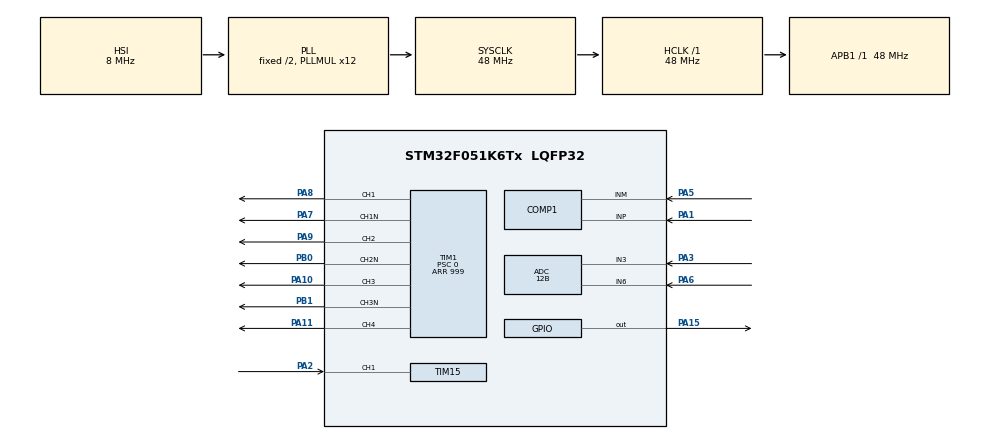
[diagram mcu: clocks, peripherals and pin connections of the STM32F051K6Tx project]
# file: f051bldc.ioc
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ADC.ClockPrescaler=ADC_CLOCK_ASYNC_DIV1
ADC.ContinuousConvMode=DISABLE
ADC.DMAContinuousRequests=ENABLE
ADC.DataAlign=ADC_DATAALIGN_RIGHT
ADC.DiscontinuousConvMode=ENABLE
ADC.EOCSelection=ADC_EOC_SEQ_CONV
ADC.EnableAnalogWatchDog=false
ADC.ExternalTrigConv=ADC_EXTERNALTRIGCONV_T1_CC4
ADC.ExternalTrigConvEdge=ADC_EXTERNALTRIGCONVEDGE_RISING
ADC.LowPowerAutoPowerOff=DISABLE
ADC.LowPowerAutoWait=DISABLE
ADC.Overrun=ADC_OVR_DATA_PRESERVED
ADC.Resolution=ADC_RESOLUTION_12B
ADC.SamplingTime=ADC_SAMPLETIME_239CYCLES_5
ADC.ScanConvMode=ADC_SCAN_DIRECTION_FORWARD
COMP1.Hysteresis=COMP_HYSTERESIS_LOW
COMP1.TriggerMode=COMP_TRIGGERMODE_IT_RISING_FALLING
Dma.ADC.1.Direction=DMA_PERIPH_TO_MEMORY
Dma.ADC.1.Instance=DMA1_Channel1
Dma.ADC.1.MemDataAlignment=DMA_MDATAALIGN_WORD
Dma.ADC.1.MemInc=DMA_MINC_ENABLE
Dma.ADC.1.Mode=DMA_CIRCULAR
Dma.ADC.1.PeriphDataAlignment=DMA_PDATAALIGN_WORD
Dma.ADC.1.PeriphInc=DMA_PINC_DISABLE
Dma.ADC.1.Priority=DMA_PRIORITY_LOW
Dma.Request0=TIM15_CH1/UP/TRIG/COM
Dma.Request1=ADC
Dma.TIM15_CH1/UP/TRIG/COM.0.Direction=DMA_PERIPH_TO_MEMORY
Dma.TIM15_CH1/UP/TRIG/COM.0.Instance=DMA1_Channel5
Dma.TIM15_CH1/UP/TRIG/COM.0.MemDataAlignment=DMA_MDATAALIGN_WORD
Dma.TIM15_CH1/UP/TRIG/COM.0.MemInc=DMA_MINC_ENABLE
Dma.TIM15_CH1/UP/TRIG/COM.0.Mode=DMA_NORMAL
Dma.TIM15_CH1/UP/TRIG/COM.0.PeriphDataAlignment=DMA_PDATAALIGN_HALFWORD
Dma.TIM15_CH1/UP/TRIG/COM.0.PeriphInc=DMA_PINC_DISABLE
Dma.TIM15_CH1/UP/TRIG/COM.0.Priority=DMA_PRIORITY_MEDIUM
IWDG.Prescaler=IWDG_PRESCALER_16
IWDG.Reload=4000
IWDG.Window=4095
Mcu.Family=STM32F0
Mcu.Name=STM32F051K6Tx
Mcu.Package=LQFP32
NVIC.ADC1_COMP_IRQn=true\:0\:0\:true\:false\:true\:false\:true
NVIC.DMA1_Channel1_IRQn=true\:2\:0\:true\:false\:true\:false\:true
NVIC.DMA1_Channel4_5_IRQn=true\:2\:0\:true\:false\:true\:false\:true
NVIC.TIM16_IRQn=true\:1\:0\:true\:false\:true\:true\:true
PA1.Mode=INP
PA1.Signal=COMP1_INP
PA10.Signal=S_TIM1_CH3
PA11.Signal=S_TIM1_CH4
PA13.Mode=Serial_Wire
PA13.Signal=SYS_SWDIO
PA14.Mode=Serial_Wire
PA14.Signal=SYS_SWCLK
PA15.Signal=GPIO_Output
PA2.Signal=S_TIM15_CH1
PA3.Mode=IN3
PA3.Signal=ADC_IN3
PA5.Mode=INM
PA5.Signal=COMP1_INM
PA6.Mode=IN6
PA6.Signal=ADC_IN6
PA7.Mode=PWM Generation1 CH1 CH1N
PA7.Signal=TIM1_CH1N
PA8.Signal=S_TIM1_CH1
PA9.Signal=S_TIM1_CH2
PB0.Mode=PWM Generation2 CH2 CH2N
PB0.Signal=TIM1_CH2N
PB1.Mode=PWM Generation3 CH3 CH3N
PB1.Signal=TIM1_CH3N
ProjectManager.HeapSize=0x200
ProjectManager.StackSize=0x400
ProjectManager.TargetToolchain=TrueSTUDIO
RCC.AHBFreq_Value=48000000
RCC.APB1Freq_Value=48000000
RCC.APB1TimFreq_Value=48000000
RCC.HCLKFreq_Value=48000000
RCC.PLLMUL=RCC_PLL_MUL12
RCC.SYSCLKFreq_VALUE=48000000
RCC.SYSCLKSource=RCC_SYSCLKSOURCE_PLLCLK
SH.S_TIM15_CH1.0=TIM15_CH1,Input_Capture1_from_TI1
SH.S_TIM15_CH1.1=TIM15_CH1,TriggerSource_TI1FP1
SH.S_TIM1_CH1.0=TIM1_CH1,PWM Generation1 CH1 CH1N
SH.S_TIM1_CH2.0=TIM1_CH2,PWM Generation2 CH2 CH2N
SH.S_TIM1_CH3.0=TIM1_CH3,PWM Generation3 CH3 CH3N
SH.S_TIM1_CH4.0=TIM1_CH4,PWM Generation4 CH4
TIM1.Channel-PWM\ Generation1\ CH1\ CH1N=TIM_CHANNEL_1
TIM1.Channel-PWM\ Generation2\ CH2\ CH2N=TIM_CHANNEL_2
TIM1.Channel-PWM\ Generation3\ CH3\ CH3N=TIM_CHANNEL_3
TIM1.Channel-PWM\ Generation4\ CH4=TIM_CHANNEL_4
TIM1.CounterMode=TIM_COUNTERMODE_CENTERALIGNED1
TIM1.DeadTime=60
TIM1.Period=999
TIM1.Prescaler=0
TIM1.TIM_MasterOutputTrigger=TIM_TRGO_RESET
TIM1.TIM_MasterSlaveMode=TIM_MASTERSLAVEMODE_DISABLE
TIM15.Channel-Input_Capture1_from_TI1=TIM_CHANNEL_1
TIM15.ICPolarity_CH1=TIM_INPUTCHANNELPOLARITY_BOTHEDGE
TIM15.Period=0xffff
TIM16.Period=9000
TIM2.Period=5000
TIM2.Prescaler=100
TIM3.Period=65535
TIM3.Prescaler=10
VP_ADC_TempSens_Input.Mode=IN-TempSens
VP_IWDG_VS_IWDG.Mode=IWDG_Activate
VP_TIM15_VS_ControllerModeReset.Mode=Reset Mode
VP_TIM16_VS_ClockSourceINT.Mode=Enable_Timer
VP_TIM1_VS_ClockSourceINT.Mode=Internal
VP_TIM2_VS_ClockSourceINT.Mode=Internal
VP_TIM3_VS_ClockSourceINT.Mode=Internal
board=f051bldc

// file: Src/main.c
/**
  ******************************************************************************
  * File Name          : main.c
  * Description        : Main program body
  ******************************************************************************
  ** This notice applies to any and all portions of this file
  * that are not between comment pairs USER CODE BEGIN and
  * USER CODE END. Other portions of this file, whether
  * inserted by the user or by software development tools
  * are owned by their respective copyright owners.
  *
  * COPYRIGHT(c) 2019 STMicroelectronics
  *
  * Redistribution and use in source and binary forms, with or without modification,
  * are permitted provided that the following conditions are met:
  *   1. Redistributions of source code must retain the above copyright notice,
  *      this list of conditions and the following disclaimer.
  *   2. Redistributions in binary form must reproduce the above copyright notice,
  *      this list of conditions and the following disclaimer in the documentation
  *      and/or other materials provided with the distribution.
  *   3. Neither the name of STMicroelectronics nor the names of its contributors
  *      may be used to endorse or promote products derived from this software
  *      without specific prior written permission.
  *
  * THIS SOFTWARE IS PROVIDED BY THE COPYRIGHT HOLDERS AND CONTRIBUTORS "AS IS"
  * AND ANY EXPRESS OR IMPLIED WARRANTIES, INCLUDING, BUT NOT LIMITED TO, THE
  * IMPLIED WARRANTIES OF MERCHANTABILITY AND FITNESS FOR A PARTICULAR PURPOSE ARE
  * DISCLAIMED. IN NO EVENT SHALL THE COPYRIGHT HOLDER OR CONTRIBUTORS BE LIABLE
  * FOR ANY DIRECT, INDIRECT, INCIDENTAL, SPECIAL, EXEMPLARY, OR CONSEQUENTIAL
  * DAMAGES (INCLUDING, BUT NOT LIMITED TO, PROCUREMENT OF SUBSTITUTE GOODS OR
  * SERVICES; LOSS OF USE, DATA, OR PROFITS; OR BUSINESS INTERRUPTION) HOWEVER
  * CAUSED AND ON ANY THEORY OF LIABILITY, WHETHER IN CONTRACT, STRICT LIABILITY,
  * OR TORT (INCLUDING NEGLIGENCE OR OTHERWISE) ARISING IN ANY WAY OUT OF THE USE
  * OF THIS SOFTWARE, EVEN IF ADVISED OF THE POSSIBILITY OF SUCH DAMAGE.
  *
  ******************************************************************************
  */

#include "main.h"
#include "stm32f0xx_hal.h"

/* USER CODE BEGIN Includes */
#include "eeprom.h"
/* USER CODE END Includes */

ADC_HandleTypeDef hadc;
DMA_HandleTypeDef hdma_adc;

COMP_HandleTypeDef hcomp1;

IWDG_HandleTypeDef hiwdg;

TIM_HandleTypeDef htim1;
TIM_HandleTypeDef htim2;
TIM_HandleTypeDef htim3;
TIM_HandleTypeDef htim15;
TIM_HandleTypeDef htim16;
DMA_HandleTypeDef hdma_tim15_ch1_up_trig_com;

/* USER CODE BEGIN PV */
/* Private variables ---------------------------------------------------------*/

#define MP6531
//#define FD6288

uint16_t VirtAddVarTab[NB_OF_VAR] = {0x5555, 0x6666, 0x7777};
uint16_t VarDataTab[NB_OF_VAR] = {0, 0, 0};
uint16_t VarValue,VarDataTmp;

uint32_t ee_status;

// variables to use for eeprom function,  ie: EE_WriteVariable(VirtAddVarTab[EEvehiclemode],  vehicle_mode ;

enum userVars{
	EEvehiclemode = 0,
	EEdirection = 1,
	EEbidirection = 2,
//	EEbrake_on_stop = 3
};
char brushed_mode = 0;
char vehicle_mode = 2;    // 1 = quad mode / eeprom load mode , 2 = crawler / thruster mode,  3 = rc car mode,  4 = like car mode but with auto reverse after stop  5 = no eeprom !!!!

char bi_polar = 0;
char polling_mode = 0;  // for better low speed accuracy

int dead_time = 60;           // change to 60 for qfn

int dir_reversed = 0;   // global direction reversed set in eeprom
int step = 1;
int startcount = 0;
int deviation = 0;
uint32_t extiline;

int forcedcomcount = 0;
int commandcount = 0;
char bad_commutation = 0;

int bi_direction = 0;
char comp_pwm = 1;                      // for complementary pwm , 0 for diode freewheeling
int brake = 1;                          // apply full motor brake on stop
int start_power = 200;
char prop_brake = 0;
int prop_brake_strength = 300;
int IC_buffer_size = 64;

char prop_brake_active = 0;
int adjusted_input;

int dshotcommand = 0;
uint8_t calcCRC;
uint8_t checkCRC;
int error = 0;
int stop_time =0;

int quietmode = 0;
int count = 0;
int tempbrake = 0;

char advancedivisor = 12;                    // increase divisor to decrease advance,
char advancedivisorup = 3;
char advancedivisordown = 3;
int advance_multiplier = 10;

int dither_count;
int dither_amount = 10;

int thiszctime = 0;
int lastzctime = 0;
int sensorless = 0;
int commutation_interval = 0;
int advance = 0;                       // set proportianal to commutation time. with advance divisor
int blanktime;
int pwm_settle = 50;
int demagtime = 5;
int waitTime = 0;
char filter_level = 1;
char compit = 0;
int filter_delay = 2;

int total;

int max_servo_deviation = 90;

int filter_level_up = 8;
int filter_level_down = 8;
int forcedcount = 0;
int control_loop_count;
int zctimeout = 0;
int zc_timeout_threshold = 2400;   // depends on speed of main loop

int signaltimeout = 0;
int signal_timeout_threshold = 20000;

int temp_step;
int ROC = 1;
int tocheck = 0;

int tim2_start_arr = 9000;
int startupcountdown = 0;

int duty_cycle = 100;

int pwm = 1;
int floating = 2;
int lowside = 3;
int bemf_counts;
int k_erpm;

int degree_time;

int forward = 1;
int rising = 1;
int running = 0;
int started = 0;
char armed = 0;
int armedcount = 0;

int input_buffer_size = 64;
int smallestnumber = 20000;
uint32_t dma_buffer[64];
int propulse[4] = {0,0,0,0};
int dpulse[16] =  {0,0,0,0,0,0,0,0,0,0,0,0,0,0,0,0};

int input = 0;
int newinput =0;
int servorawinput = 0;

int voltageraw = 0;
int currentraw = 0;
int tempraw = 0;
uint32_t ADC1ConvertedValues[2] = {0,0};
int timestamp;

int compcount = 0;
int upcompcount = 0;
int falsecount = 0;
int falsethreshold = 2;
int zcfound = 1;
int threshold = 6;
int upthreshold = 6;
int forced_com_done = 0;

char dshot = 0;
char proshot = 0;
char multishot = 0;
char oneshot42 = 0;
char oneshot125 = 0;
char servoPwm = 0;

char brushed_direction_set = 0;

char inputSet = 0;

const int pwmSin[] = {128,130,132,134,136,139,141,143,
145,147,150,152,154,156,158,160,
163,165,167,169,171,173,175,177,
179,181,183,185,187,189,191,193,
195,197,199,201,202,204,206,208,
209,211,213,214,216,218,219,221,
222,224,225,227,228,229,231,232,
233,234,236,237,238,239,240,241,
242,243,244,245,246,247,247,248,
249,249,250,251,251,252,252,253,
253,253,254,254,254,255,255,255,
255,255,255,255,255,255,255,255,
254,254,254,253,253,253,252,252,
251,251,250,249,249,248,247,247,
246,245,244,243,242,241,240,239,
238,237,236,234,233,232,231,229,
228,227,225,224,222,221,219,218,
216,214,213,211,209,208,206,204,
202,201,199,197,195,193,191,189,
187,185,183,181,179,177,175,173,
171,169,167,165,163,160,158,156,
154,152,150,147,145,143,141,139,
136,134,132,130,128,125,123,121,
119,116,114,112,110,108,105,103,
101,99,97,95,92,90,88,86,
84,82,80,78,76,74,72,70,
68,66,64,62,60,58,56,54,
53,51,49,47,46,44,42,41,
39,37,36,34,33,31,30,28,
27,26,24,23,22,21,19,18,
17,16,15,14,13,12,11,10,
9,8,8,7,6,6,5,4,
4,3,3,2,2,2,1,1,
1,0,0,0,0,0,0,0,
0,0,0,0,1,1,1,2,
2,2,3,3,4,4,5,6,
6,7,8,8,9,10,11,12,
13,14,15,16,17,18,19,21,
22,23,24,26,27,28,30,31,
33,34,36,37,39,41,42,44,
46,47,49,51,53,54,56,58,
60,62,64,66,68,70,72,74,
76,78,80,82,84,86,88,90,
92,95,97,99,101,103,105,108,
110,112,114,116,119,121,123,125};

int phase_A_position;
int phase_B_position;
int phase_C_position;
int step_delay  = 100;
char stepper_sine = 0;

/* USER CODE END PV */

void SystemClock_Config(void);
static void MX_GPIO_Init(void);
static void MX_DMA_Init(void);
static void MX_ADC_Init(void);
static void MX_COMP1_Init(void);
static void MX_TIM1_Init(void);
static void MX_TIM2_Init(void);
static void MX_TIM3_Init(void);
static void MX_TIM15_Init(void);
static void MX_IWDG_Init(void);
static void MX_TIM16_Init(void);

void HAL_TIM_MspPostInit(TIM_HandleTypeDef *htim);

/* USER CODE BEGIN PFP */
/* Private function prototypes -----------------------------------------------*/
long map(long x, long in_min, long in_max, long out_min, long out_max)
{
	if (x < in_min){
		x = in_min;
	}
	if (x > in_max){
		x = in_max;
	}
	return (x - in_min) * (out_max - out_min) / (in_max - in_min) + out_min;

}

void storeEEpromConfig(){

	 EE_WriteVariable(VirtAddVarTab[EEvehiclemode], vehicle_mode);
	 EE_WriteVariable(VirtAddVarTab[EEdirection], dir_reversed);
	 EE_WriteVariable(VirtAddVarTab[EEbidirection], bi_direction);
	// EE_WriteVariable(VirtAddVarTab[EEbrake_on_stop], EEbrake_on_stop);

	// playEEpromSavedTune();
}

void loadEEpromConfig(){
	 EE_ReadVariable(VirtAddVarTab[EEvehiclemode], &VarDataTab[EEvehiclemode]);
	 EE_ReadVariable(VirtAddVarTab[EEdirection], &VarDataTab[EEdirection]);
	 EE_ReadVariable(VirtAddVarTab[EEbidirection], &VarDataTab[EEbidirection]);
//	 EE_ReadVariable(VirtAddVarTab[EEbrake_on_stop], &VarDataTab[EEbrake_on_stop]);

	 if (VarDataTab[EEvehiclemode] == 0){             // nothing in the eeprom
     storeEEpromConfig();            // store default values
	 }else{
	 vehicle_mode = VarDataTab[EEvehiclemode];
	 dir_reversed = VarDataTab[EEdirection];
	 bi_direction = VarDataTab[EEbidirection];
//	 brake = VarDataTab[EEbrake_on_stop];
	 }
}

int getAbsDif(int number1, int number2){
	int result = number1 - number2;
	if (result < 0) {
	    result = -result;
	}
	return result;
}

//////////////////////////////////PHASE 1//////////////////////
#ifdef MP6531
void phaseAPWM() {  // phaseB qfnf051 , phase A qfp32
#endif
#ifdef FD6288
void phaseBPWM() {
#endif

		if(!comp_pwm  || prop_brake_active){            // for future
		LL_GPIO_SetPinMode(GPIOB, GPIO_PIN_0, LL_GPIO_MODE_OUTPUT);
		GPIOB->BRR = GPIO_PIN_0;
		}else{
		LL_GPIO_SetPinMode(GPIOB, GPIO_PIN_0, LL_GPIO_MODE_ALTERNATE); // low
		}
		LL_GPIO_SetPinMode(GPIOA, GPIO_PIN_9, LL_GPIO_MODE_ALTERNATE);  // high

	}

#ifdef MP6531
void phaseAFLOAT() {  // phaseB qfnf051 , phase A qfp32
#endif
#ifdef FD6288
void phaseBFLOAT() {
#endif

		LL_GPIO_SetPinMode(GPIOB, GPIO_PIN_0, LL_GPIO_MODE_OUTPUT);
		GPIOB->BRR = GPIO_PIN_0;
		LL_GPIO_SetPinMode(GPIOA, GPIO_PIN_9, LL_GPIO_MODE_OUTPUT);
		GPIOA->BRR = GPIO_PIN_9;
	}

#ifdef MP6531
void phaseALOW() {  // phaseB qfnf051 , phase A qfp32
#endif
#ifdef FD6288
void phaseBLOW() {
#endif

	        // low mosfet on
		LL_GPIO_SetPinMode(GPIOB, GPIO_PIN_0, LL_GPIO_MODE_OUTPUT);
		GPIOB->BSRR = GPIO_PIN_0;
		LL_GPIO_SetPinMode(GPIOA, GPIO_PIN_9, LL_GPIO_MODE_OUTPUT);
		GPIOA->BRR = GPIO_PIN_9;
	}

//////////////////////////////PHASE 2//////////////////////////////////////////////////

#ifdef MP6531
void phaseBPWM() {                                // phase c qfn , phase b qfp
#endif
#ifdef FD6288
void phaseCPWM() {
#endif

		if (!comp_pwm || prop_brake_active){
			LL_GPIO_SetPinMode(GPIOA, GPIO_PIN_7, LL_GPIO_MODE_OUTPUT);
			GPIOA->BRR = GPIO_PIN_7;
		}else{
		LL_GPIO_SetPinMode(GPIOA, GPIO_PIN_7, LL_GPIO_MODE_ALTERNATE);
		}
		LL_GPIO_SetPinMode(GPIOA, GPIO_PIN_8, LL_GPIO_MODE_ALTERNATE);

	}

#ifdef MP6531
void phaseBFLOAT() {                                // phase c qfn , phase b qfp
#endif
#ifdef FD6288
void phaseCFLOAT() {
#endif

	         // floating
		LL_GPIO_SetPinMode(GPIOA, GPIO_PIN_7, LL_GPIO_MODE_OUTPUT);
		GPIOA->BRR = GPIO_PIN_7;
		LL_GPIO_SetPinMode(GPIOA, GPIO_PIN_8, LL_GPIO_MODE_OUTPUT);
		GPIOA->BRR = GPIO_PIN_8;
	}

#ifdef MP6531
void phaseBLOW() {                                // phase c qfn , phase b qfp
#endif
#ifdef FD6288
void phaseCLOW() {
#endif

	            // lowside
		LL_GPIO_SetPinMode(GPIOA, GPIO_PIN_7, LL_GPIO_MODE_OUTPUT);
		GPIOA->BSRR = GPIO_PIN_7;
		LL_GPIO_SetPinMode(GPIOA, GPIO_PIN_8, LL_GPIO_MODE_OUTPUT);
		GPIOA->BRR = GPIO_PIN_8;
	}

///////////////////////////////////////////////PHASE 3 /////////////////////////////////////////////////

#ifdef MP6531
void phaseCPWM() {                    // phaseA qfn , phase C qfp
#endif
#ifdef FD6288
void phaseAPWM() {
#endif

		if (!comp_pwm || prop_brake_active){
			LL_GPIO_SetPinMode(GPIOB, GPIO_PIN_1, LL_GPIO_MODE_OUTPUT);
			GPIOB->BRR = GPIO_PIN_1;
			}else{
		LL_GPIO_SetPinMode(GPIOB, GPIO_PIN_1, LL_GPIO_MODE_ALTERNATE);
			}
		LL_GPIO_SetPinMode(GPIOA, GPIO_PIN_10, LL_GPIO_MODE_ALTERNATE);

	}

#ifdef MP6531
void phaseCFLOAT() {                    // phaseA qfn , phase C qfp
#endif
#ifdef FD6288
void phaseAFLOAT() {
#endif

		LL_GPIO_SetPinMode(GPIOB, GPIO_PIN_1, LL_GPIO_MODE_OUTPUT);
		GPIOB->BRR = GPIO_PIN_1;
		LL_GPIO_SetPinMode(GPIOA, GPIO_PIN_10, LL_GPIO_MODE_OUTPUT);
		GPIOA->BRR = GPIO_PIN_10;
	}

#ifdef MP6531
void phaseCLOW() {                    // phaseA qfn , phase C qfp
#endif
#ifdef FD6288
void phaseALOW() {
#endif

		LL_GPIO_SetPinMode(GPIOB, GPIO_PIN_1, LL_GPIO_MODE_OUTPUT);
		GPIOB->BSRR = GPIO_PIN_1;
		LL_GPIO_SetPinMode(GPIOA, GPIO_PIN_10, LL_GPIO_MODE_OUTPUT);
		GPIOA->BRR = GPIO_PIN_10;
	}

void  comStep (int newStep){
//TIM14->CNT = 0;
switch(newStep)
{

        case 1:			//A-B
        	phaseAPWM();
        	phaseBLOW();
        	phaseCFLOAT();
        	break;

        case 2:		// C-B
        	phaseAFLOAT();
        	phaseBLOW();
        	phaseCPWM();
        	break;

        case 3:	// C-A
        	phaseALOW();
        	phaseBFLOAT();
        	phaseCPWM();
        	break;

        case 4:// B-A
        	phaseALOW();
        	phaseBPWM();
        	phaseCFLOAT();
        	break;

        case 5:    // B-C
        	phaseAFLOAT();
        	phaseBPWM();
        	phaseCLOW();
        	break;

        case 6:      // A-C
        	phaseAPWM();
        	phaseBFLOAT();
        	phaseCLOW();
        	break;
	}

//stop_time = TIM14->CNT;

}

void allOff() {                   // coast
	phaseAFLOAT();
	phaseBFLOAT();
	phaseCFLOAT();
}

void fullBrake(){                     // full braking shorting all low sides
	phaseALOW();
	phaseBLOW();
	phaseCLOW();
}

void proBrake(){                    // duty cycle controls braking strength
//	prop_brake_active = 1;       // will turn off lower fets so only high side is active
	phaseAPWM();
	phaseBPWM();
	phaseCPWM();
}

void changeCompInput() {
//	TIM2->CNT = 0;
//	HAL_COMP_Stop_IT(&hcomp1);            // done in comparator routine

	if (step == 1 || step == 4) {   // c floating
	//	hcomp1.Init.InvertingInput = COMP_INVERTINGINPUT_IO1;
		COMP->CSR = 0b1100001;
	}

	if (step == 2 || step == 5) {     // a floating
#ifdef MP6531
		//COMP->CSR = 0x40;
	//	hcomp1.Init.InvertingInput = COMP_INVERTINGINPUT_DAC1;
		COMP->CSR = 0b1000001;                        /// if f051k6  step 2 , 5 is dac 1 ( swap comp input)
#endif
#ifdef FD6288
	//hcomp1.Init.InvertingInput = COMP_INVERTINGINPUT_DAC2;
		COMP->CSR = 0b1010001;
#endif
	}

	if (step == 3 || step == 6) {      // b floating
#ifdef MP6531
		//COMP->CSR = 0x50
	//	hcomp1.Init.InvertingInput = COMP_INVERTINGINPUT_DAC2;
		COMP->CSR = 0b1010001;
#endif
#ifdef FD6288
	//	hcomp1.Init.InvertingInput = COMP_INVERTINGINPUT_DAC1;
		COMP->CSR = 0b1000001;
#endif
	}
	if (rising){

		EXTI->RTSR = 0x0;
	EXTI->FTSR = 0x200000;

	//	hcomp1.Init.TriggerMode = COMP_TRIGGERMODE_IT_FALLING;   // polarity of comp output reversed
	}else{                          // falling bemf

	EXTI->FTSR = 0x0;
	EXTI->RTSR = 0x200000;
	//	hcomp1.Init.TriggerMode = COMP_TRIGGERMODE_IT_RISING;
	}

//	if (HAL_COMP_Init(&hcomp1) != HAL_OK) {
//		_Error_Handler(__FILE__, __LINE__);
//	}
////stop_time = TIM2->CNT;
}
void pollingChangeCompInput() {

	HAL_COMP_Stop(&hcomp1);

	if (step == 1 || step == 4) {   // c floating
		hcomp1.Init.InvertingInput = COMP_INVERTINGINPUT_IO1;
	}

	if (step == 2 || step == 5) {     // a floating
#ifdef MP6531
			hcomp1.Init.InvertingInput = COMP_INVERTINGINPUT_DAC1;  /// if f051k6  step 2 , 5 is dac 1 ( swap comp input)
#endif
#ifdef FD6288
	hcomp1.Init.InvertingInput = COMP_INVERTINGINPUT_DAC2;
#endif
	}

	if (step == 3 || step == 6) {      // b floating
#ifdef MP6531
			hcomp1.Init.InvertingInput = COMP_INVERTINGINPUT_DAC2;  /// if f051k6  step 2 , 5 is dac 1 ( swap comp input)
#endif
#ifdef FD6288
	hcomp1.Init.InvertingInput = COMP_INVERTINGINPUT_DAC1;
#endif
	}

	if (HAL_COMP_Init(&hcomp1) != HAL_OK) {
		_Error_Handler(__FILE__, __LINE__);
	}

	if (HAL_COMP_Start(&hcomp1) != HAL_OK) {
		/* Initialization Error */
		Error_Handler();
	}

}

void commutate() {
//	TIM2->CNT = 0;
	if (forward == 1){
		step++;
		if (step > 6) {
			step = 1;
		}
		if (step == 1 || step == 3 || step == 5) {
			rising = 1;                                // is back emf rising or falling
		}
		if (step == 2 || step == 4 || step == 6) {
			rising = 0;
		}
	}
	if (forward == 0){
		step--;
		if (step < 1) {
			step = 6;
		}
		if (step == 1 || step == 3 || step == 5) {
			rising = 0;
		}
		if (step == 2 || step == 4 || step == 6) {
			rising = 1;
		}
	}

	//TIM2->CNT = 0;
	if (input > 47){
comStep(step);
	}

	if((bemf_counts > 50 && duty_cycle > 180)){
		polling_mode = 0;

	}else{
		polling_mode = 1;
	}
	if (duty_cycle < 180 || commutation_interval > 10000){
		polling_mode = 1;
	}

	if(!polling_mode){
		changeCompInput();
		EXTI->IMR |= (1 << 21);
	}else{
		pollingChangeCompInput();
	}
	zcfound = 0;
//	falseAlarm = 0;
//	compCount = 0;
//	upcompCount = 0;

	//stop_time = TIM2->CNT;
}

void HAL_TIM_PeriodElapsedCallback(TIM_HandleTypeDef *htim){

			if (htim->Instance==TIM16)
			{

			if(inputSet == 1){
				 if (!HAL_GPIO_ReadPin(GPIOA, GPIO_PIN_2)){

		     HAL_TIM_IC_Stop_DMA(&htim15,TIM_CHANNEL_1);
			 TIM15->CNT = 0;
//			 for (int i = 0; i < 8; i++){
//			 							dma_buffer[i]=0;
//			 						}

				 HAL_TIM_IC_Start_DMA(&htim15, TIM_CHANNEL_1, dma_buffer , IC_buffer_size);
			 }

			 }

		}

}

void startMotor() {

 startcount++;

    char decaystate = comp_pwm;
    sensorless = 0;
	if (running == 0){
		EXTI->IMR &= ~(1 << 21);
		EXTI->PR &=~(1 << 21);

	//	HAL_COMP_Stop_IT(&hcomp1);
		comp_pwm = 1;

	commutate();
//	HAL_Delay(5);
	//commutate();
	commutation_interval = 20000;
	TIM2->CNT = 0;
//	TIM2->CNT = 0;
//	TIM2->ARR = commutation_interval * 2;
	running = 1;
//	if (HAL_COMP_Start_IT(&hcomp1) != HAL_OK) {
			/* Initialization Error */
//			Error_Handler();
//		}
	if(!polling_mode){
	EXTI->IMR |= (1 << 21);
	}
	}else{
		if (HAL_COMP_Start(&hcomp1) != HAL_OK) {
			/* Initialization Error */
			Error_Handler();
		}
	}
	comp_pwm = decaystate;    // return to normal
	sensorless = 1;
	startupcountdown =0;
	bemf_counts = 0;

}

void forcedCommutation(){
	HAL_COMP_Stop_IT(&hcomp1);
    TIM2->CNT = commutation_interval / 2;
    commutate();
    while (TIM2->CNT - commutation_interval / 2  <  blanktime){}
	if (HAL_COMP_Start_IT(&hcomp1) != HAL_OK) {
		/* Initialization Error */
		Error_Handler();
	}

}

void HAL_COMP_TriggerCallback(COMP_HandleTypeDef *hcomp) {
//	thiszctime = TIM2->CNT;
//	EXTI->IMR &= (0 << 21);
//		EXTI->PR &=(0 << 21);
if ((TIM2->CNT < commutation_interval >> 1)&& bemf_counts > 3 ){

//	EXTI->IMR |= (1 << 21);
	return;
}
while (TIM2->CNT - thiszctime < filter_delay){

}
compit +=1;
if (compit > 100){
	EXTI->IMR &= ~(1 << 21);
	EXTI->PR &=~(1 << 21);
//		input = 0;
	error = 1;
	return;
}
//	while(TIM2->CNT - thiszctime  < filter_delay){
//
//	}
		if (rising){
		//	advancedivisor = advancedivisorup;
			for (int i = 0; i < filter_level; i++){
			if (HAL_COMP_GetOutputLevel(&hcomp1) == COMP_OUTPUTLEVEL_HIGH){
		//		GPIOA->BRR = GPIO_PIN_15;

			//	EXTI->IMR |= (1 << 21);
				return;
			//	EXTI->IMR |= (1 << 21);
			}
			}

		}else{
		//	advancedivisor = advancedivisordown;
			for (int i = 0; i < filter_level; i++){
			if (HAL_COMP_GetOutputLevel(&hcomp1) == COMP_OUTPUTLEVEL_LOW){
		//		GPIOA->BRR = GPIO_PIN_15;
				//EXTI->IMR |= (1 << 21);
				return;
			}
			}

		}
		thiszctime = TIM2->CNT;

	TIM2->CNT = 0;
	zctimeout = 0;
	//	HAL_COMP_Stop_IT(&hcomp1);
	while (TIM2->CNT  < waitTime){
	}

	EXTI->IMR &= ~(1 << 21);
	EXTI->PR &=~(1 << 21);
//	TIM1->CNT = duty_cycle;
	commutate();
	commutation_interval = ((2*commutation_interval) + thiszctime) / 3;
		degree_time = commutation_interval >> 5;                          // about 1.85 degrees per unit
			advance = degree_time * advance_multiplier;                     //  * 16 would be about 30 degrees
//	advance = commutation_interval>>2 ;
	waitTime = (commutation_interval >> 1) - advance;
	if (waitTime < 0){
			waitTime = 0;
		}
			blanktime = commutation_interval >>3 ;                               // divided by 8
			bemf_counts++;
			while (TIM2->CNT < waitTime + blanktime){

			}
			EXTI->IMR |= (1 << 21);
//				if (HAL_COMP_Start_IT(&hcomp1) != HAL_OK) {
//						/* Initialization Error */
//			//			Error_Handler();
//					}
}

void checkForZeroCross(){
	if(!zcfound){

			//			  if (step == 2 || step == 4 || step == 6){
			if (rising == 0){
				if (HAL_COMP_GetOutputLevel(&hcomp1) == COMP_OUTPUTLEVEL_LOW){
					falsecount++;
					if (falsecount > falsethreshold){
					compcount = 0;
					zcfound = 0;
					falsecount = 0;
					}

				}

				if (HAL_COMP_GetOutputLevel(&hcomp1) == COMP_OUTPUTLEVEL_HIGH){

					compcount++;
				}
					if (compcount > threshold){
							zcfound = 1;
							zctimeout = 0;
							compcount = 0;
							bemf_counts++;
							falsecount = 0;
							thiszctime = TIM2->CNT;
							TIM2->CNT = 0;
							forced_com_done = 0;

						    commutation_interval = ((2*commutation_interval) + thiszctime) / 3;
							degree_time = commutation_interval >> 5;                          // about 1.85 degrees per unit
							advance = degree_time * advance_multiplier;                     //  * 16 would be about 30 degrees
							waitTime = (commutation_interval >> 1) - advance;

							if (sensorless){
								while (TIM2->CNT  < waitTime){
								}
								commutate();

							}
							zcfound = 0;

						}
			}

			if (rising == 1){
				if (HAL_COMP_GetOutputLevel(&hcomp1) == COMP_OUTPUTLEVEL_HIGH){
					falsecount++;
					if (falsecount > falsethreshold){
					upcompcount = 0;
					zcfound = 0;
					falsecount = 0;
					}

				}

				if (HAL_COMP_GetOutputLevel(&hcomp1) == COMP_OUTPUTLEVEL_LOW){
					//		GPIOA->BSRR = GPIO_PIN_15;
					upcompcount++;
				}
					if (upcompcount > upthreshold){
							zcfound = 1;
							zctimeout = 0;
							upcompcount = 0;
							falsecount = 0;
							bemf_counts++;
				//			GPIOA->BSRR = GPIO_PIN_15;
								thiszctime = TIM2->CNT;
								TIM2->CNT = 0;
								forced_com_done = 0;

							    commutation_interval = ((2*commutation_interval) + thiszctime) / 3;
								degree_time = commutation_interval >> 5;                          // about 1.85 degrees per unit
								advance = degree_time * advance_multiplier;
								waitTime = (commutation_interval >> 1) - advance;
								if (sensorless){
									while (TIM2->CNT < waitTime){
									}
									commutate();
								}
								zcfound = 0;
		//						lastzctime = thiszctime;
						}
			}
	}
}

void playStartupTune(){
	TIM1->PSC = 75;
	TIM1->CCR1 = 5;
	TIM1->CCR2 = 5;
	TIM1->CCR3 = 5;
	comStep(3);
	HAL_Delay(100);
	TIM1->PSC = 50;
	HAL_Delay(100);
	TIM1->PSC = 25;
	HAL_Delay(100);
	allOff();
	TIM1->PSC = 0;
}

void playInputTune(){
	TIM1->PSC = 100;
	TIM1->CCR1 = 5;
	TIM1->CCR2 = 5;
	TIM1->CCR3 = 5;
	comStep(6);
	HAL_Delay(100);
	TIM1->PSC = 50;
	HAL_Delay(100);
	allOff();
	TIM1->PSC = 0;
}

void getADCs(){
	//voltageraw = ADC1ConvertedValues[0];
	currentraw = ADC1ConvertedValues[0];
	tempraw = ADC1ConvertedValues[1];

}

void HAL_ADC_ConvCpltCallback(ADC_HandleTypeDef* hadc)
{
	getADCs();
}

void detectInput(){
	smallestnumber = 20000;
	dshot = 0;
	proshot = 0;
	multishot = 0;
	oneshot42 = 0;
	oneshot125 = 0;
	servoPwm = 0;
//	int lastnumber = dma_buffer[0];
	for ( int j = 1 ; j < input_buffer_size; j++){

		if(dma_buffer[j]  < smallestnumber){ // blank space
			smallestnumber = dma_buffer[j];
		}

	}

	if ((smallestnumber > 3)&&(smallestnumber < 22)){
		dshot = 1;
		TIM15->PSC = 20;
		IC_buffer_size = 32;
		TIM16->ARR = 8000;
	}
	if ((smallestnumber > 22)&&(smallestnumber < 30)){
			dshot = 1;
			TIM15->PSC = 32;
			TIM16->PSC = 1;
			TIM16->ARR = 8000;
			IC_buffer_size = 32;
		}

	if ((smallestnumber > 40 )&&(smallestnumber < 80)){
		proshot = 1;
		TIM15->PSC = 5;
		IC_buffer_size = 8;
		TIM16->ARR = 8000;
	}
//	if ((smallestnumber > 100 )&&(smallestnumber < 400)){
//		multishot = 1;
//	}
//	if ((smallestnumber > 2000 )&&(smallestnumber < 3000)){
//		oneshot42 = 1;
//	}
//	if ((smallestnumber > 3000 )&&(smallestnumber < 7000)){
//		oneshot125 = 1;
//	}
	if (smallestnumber > 100){
		servoPwm = 1;
		TIM15->PSC = 47;
//		TIM16->PSC = 47;
//		TIM16->ARR = 10000;
		HAL_TIM_Base_Stop(&htim16);
		IC_buffer_size = 6;

	}

	if (smallestnumber == 0){
		inputSet = 0;
	}else{

		inputSet = 1;

		HAL_Delay(50);
		//	playInputTune();
	}
	HAL_TIM_IC_Start_DMA(&htim15, TIM_CHANNEL_1, dma_buffer , IC_buffer_size);
}

void computeProshotDMA(){

total = dma_buffer[1]+ dma_buffer[2] + dma_buffer[3] + dma_buffer[4]+ dma_buffer[5] + dma_buffer[6] + dma_buffer[7];

   if (( total < 118 && total > 98)&& (dma_buffer[0]> 100)){
   for (int i = 1; i < 8; i +=2){
    propulse[(i-1) / 2] = (dma_buffer[i] - 7);
					}
   }else{

	   return;
   }
	calcCRC = ((propulse[0]^propulse[1]^propulse[2])<<3
							|(propulse[0]^propulse[1]^propulse[2])<<2
							|(propulse[0]^propulse[1]^propulse[2])<<1
							|(propulse[0]^propulse[1]^propulse[2]));

	checkCRC = (propulse[3]<<3 | propulse[3]<<2 | propulse[3]<<1 | propulse[3]);
    if ( checkCRC == calcCRC){
    	tocheck = ((propulse[0]<<7 | propulse[1]<<3 | propulse[2]>>1));
    }else{
 //   	error++;
    }
    if (tocheck > 47 && tocheck < 2048){
    	newinput = tocheck ;
    				commandcount = 0;

    			}else if (tocheck > 1 && tocheck < 48 && input == 0){

    					dshotcommand = tocheck ;
    			}else{
    				commandcount++;
    				if (commandcount > 1){
    				newinput = tocheck ;
    			    commandcount = 0;
    			}
    			}

}

void computeDshotDMA(){

	if (dma_buffer[0] < 20){
		return;
	}

//	for (int i = 1; i < 32; i+=2){
//		dpulse[(i-1)>>1] = dma_buffer[i] ;
//	}
	 calcCRC = ((dma_buffer[1]^dma_buffer[9]^dma_buffer[17])<<3
			          |(dma_buffer[3]^dma_buffer[11]^dma_buffer[19])<<2
					|(dma_buffer[5]^dma_buffer[13]^dma_buffer[21])<<1
					|(dma_buffer[7]^dma_buffer[15]^dma_buffer[23])
				);
//	 calcCRC = ((dpulse[0]^dpulse[4]^dpulse[8])<<3
//			          |(dpulse[1]^dpulse[5]^dpulse[9])<<2
//					|(dpulse[2]^dpulse[6]^dpulse[10])<<1
//					|(dpulse[3]^dpulse[7]^dpulse[11])
//				);
//	 checkCRC = (dpulse[12]<<3 | dpulse[13]<<2 | dpulse[14]<<1 | dpulse[15]);
	 checkCRC = (dma_buffer[25]<<3 | dma_buffer[27]<<2 | dma_buffer[29]<<1 | dma_buffer[31]);
//
			if(calcCRC == checkCRC){
				tocheck = (
						dma_buffer[1]<<10 | dma_buffer[3]<<9 | dma_buffer[5]<<8 | dma_buffer[7]<<7
					| dma_buffer[9]<<6 | dma_buffer[11]<<5 | dma_buffer[13]<<4 | dma_buffer[15]<<3
					| dma_buffer[17]<<2 | dma_buffer[19]<<1 | dma_buffer[21]);
//				success++;
				}else{
					error++;
				}

			if (tocheck > 47 && tocheck < 2048){
				newinput = tocheck;
				commandcount = 0;
			}else if (tocheck > 1 && tocheck < 48 && input == 0){

					dshotcommand = tocheck ;

			}else{
				commandcount++;
				if (commandcount > 1){
				newinput = tocheck ;
			    commandcount = 0;
			}
			}

}

void computeMSInput(){

	int lastnumber = dma_buffer[0];
	for ( int j = 1 ; j < 2; j++){

		if(((dma_buffer[j] - lastnumber) < 1500) && ((dma_buffer[j] - lastnumber) > 0)){ // blank space

			newinput = map((dma_buffer[j] - lastnumber),243,1200, 0, 2000);
			break;
		}
		lastnumber = dma_buffer[j];
	}
}

void computeOS125Input(){

	int lastnumber = dma_buffer[0];
	for ( int j = 1 ; j < 2; j++){

		if(((dma_buffer[j] - lastnumber) < 12300) && ((dma_buffer[j] - lastnumber) > 0)){ // blank space

			newinput = map((dma_buffer[j] - lastnumber),6500,12000, 0, 2000);
			break;
		}
		lastnumber = dma_buffer[j];
	}
}

void computeOS42Input(){

	int lastnumber = dma_buffer[0];
	for ( int j = 1 ; j < 2; j++){

		if(((dma_buffer[j] - lastnumber) < 4500) && ((dma_buffer[j] - lastnumber) > 0)){ // blank space

			newinput = map((dma_buffer[j] - lastnumber),2020, 4032, 0, 2000);
			break;
		}
		lastnumber = dma_buffer[j];
	}
}

void computeServoInput(){

	if ( dma_buffer[1] < 2000 && dma_buffer[1] > 1000){
		if(dma_buffer[2]< 1000 || dma_buffer[2] > 2500){

		servorawinput = map(dma_buffer[1], 1100,2000,0,2000);
		}
	}else if( dma_buffer[2] < 2000 && dma_buffer[2] > 1000) {
		if(dma_buffer[1]< 1000 || dma_buffer[1] > 2500){
		servorawinput = map(dma_buffer[2], 1100,2000,0,2000);
		}
	}

	if (servorawinput - newinput > max_servo_deviation){
		newinput += max_servo_deviation;
	}else if(newinput - servorawinput > max_servo_deviation){
		newinput -= max_servo_deviation;
	}else{
		newinput = servorawinput;
	}

}

void transferComplete(){
//	TIM2->CNT = 0;
//	compit = 0;
	signaltimeout = 0;
//	HAL_GPIO_TogglePin(GPIOC, GPIO_PIN_3);

	if (inputSet == 1){

		if (dshot == 1){
			computeDshotDMA();
//			HAL_TIM_IC_Start_DMA(&htim15, TIM_CHANNEL_1, dma_buffer , 64);
	//		stop_time = TIM2->CNT;
			return;
		}
		if (proshot == 1){
			computeProshotDMA();
	//		stop_time = TIM2->CNT;
	//		HAL_TIM_IC_Start_DMA(&htim15, TIM_CHANNEL_1, dma_buffer , 16);
			return;
		}

		if  (servoPwm == 1){
			computeServoInput();

		//	if (!HAL_GPIO_ReadPin(GPIOA, GPIO_PIN_2)){
			//	HAL_TIM_IC_Start_DMA(&htim15, TIM_CHANNEL_1, dma_buffer , 3);
		//	}else{
				HAL_TIM_IC_Start_DMA(&htim15, TIM_CHANNEL_1, dma_buffer , 3);
		//	}

		}
//		if  (multishot){
//			computeMSInput();
//			HAL_TIM_IC_Start_DMA(&htim15, TIM_CHANNEL_1, dma_buffer , 3);
//
//		}
//		if  (oneshot125){
//			computeOS125Input();
//			HAL_TIM_IC_Start_DMA(&htim15, TIM_CHANNEL_1, dma_buffer , 3);
//
//		}
//		if  (oneshot42){
//			computeOS42Input();
//			HAL_TIM_IC_Start_DMA(&htim15, TIM_CHANNEL_1, dma_buffer , 3);
//
//		}

}

}
/* USER CODE END PFP */

int main(void)
{

  /* MCU Configuration----------------------------------------------------------*/

  /* Reset of all peripherals, Initializes the Flash interface and the Systick. */
  HAL_Init();

  /* Configure the system clock */
  SystemClock_Config();

  /* USER CODE BEGIN SysInit */
  HAL_FLASH_Unlock();
  EE_Init();
//  HAL_Delay(10);
  /* USER CODE END SysInit */

  /* Initialize all configured peripherals */
  MX_GPIO_Init();
  MX_DMA_Init();
  MX_ADC_Init();
  MX_COMP1_Init();
  MX_TIM1_Init();
  MX_TIM2_Init();
  MX_TIM3_Init();
  MX_TIM15_Init();

  MX_TIM16_Init();

  /* USER CODE BEGIN 2 */
	HAL_TIM_PWM_Start(&htim1, TIM_CHANNEL_1);
	HAL_TIMEx_PWMN_Start(&htim1, TIM_CHANNEL_1);
	HAL_TIM_PWM_Start(&htim1, TIM_CHANNEL_2);
	HAL_TIMEx_PWMN_Start(&htim1, TIM_CHANNEL_2);
	HAL_TIM_PWM_Start(&htim1, TIM_CHANNEL_3);
	HAL_TIMEx_PWMN_Start(&htim1, TIM_CHANNEL_3);

	HAL_TIM_Base_Start(&htim2);
	HAL_TIM_Base_Start_IT(&htim16);
	HAL_TIM_Base_Start(&htim3);
	//  HAL_Delay(500);
	for ( int i = 0; i < vehicle_mode; i++){
	playStartupTune();
	HAL_Delay(100);
	}
	MX_IWDG_Init();
	if (vehicle_mode == 1){                    // quad single direction
		loadEEpromConfig();
	}
	if (vehicle_mode == 2){                   // crawler or thruster
		 bi_direction = 1;
		 comp_pwm = 1;                      // for complementary pwm , 0 for diode freewheeling
		 brake = 1;                          // apply full motor brake on stop
	//	 start_power = 150;

	}
	if (vehicle_mode == 3){                 // rc car 50 percent brake on reverse.
		 bi_direction = 1;
		 comp_pwm = 0;                      // for complementary pwm , 0 for diode freewheeling
		 brake = 0;                          // apply full motor brake on stop
	//	 start_power = 150;
		 prop_brake = 1;
		 prop_brake_strength = 900;
	}
	if (vehicle_mode == 4){                 // rc car 50 percent brake on reverse.
			 bi_direction = 1;
			 comp_pwm = 0;                      // for complementary pwm , 0 for diode freewheeling
			 brake = 0;                          // apply full motor brake on stop
	//		 start_power = 150;
			 prop_brake = 1;
			 prop_brake_strength = 800;
		}

	if (vehicle_mode == 5){                    // quad single direction no eeprom

	}

	if (HAL_TIM_OC_Start_IT(&htim1, TIM_CHANNEL_4) != HAL_OK)
	{
		_Error_Handler(__FILE__, __LINE__);
	}
	HAL_TIM_IC_Start_DMA(&htim15, TIM_CHANNEL_1, dma_buffer , 64);
//	if (HAL_ADC_Start_DMA(&hadc, (uint32_t*)ADC1ConvertedValues, 2) != HAL_OK){            // for adc turn this on!!!!
//		Error_Handler();
//
//	}
		if(HAL_COMP_Start_IT(&hcomp1) != HAL_OK)
		{
			/* Initialization Error */
			Error_Handler();
		}
	//
//	if(HAL_IWDG_Init(&hiwdg) != HAL_OK)
//	{
//		/* Initialization Error */
//		Error_Handler();
//	}

	if(bi_direction){
		newinput = 1001;
	//	start_power = 175;
	}

	if (dir_reversed == 1){
		forward = 0;
	}else{
		forward = 1;
	}

	//proBrake();
	TIM1->CCR1 = 1;
	TIM1->CCR2 = 1;
	TIM1->CCR3 = 1;

	TIM1->CCR4 = 800;

	if (!brushed_mode && bi_polar){          // sanity check, turn off bipolar pwm if brushed mode is not selected
		bi_polar = 0;
	}
	if(bi_polar){
		comp_pwm = 1;
	}

//	changeCompInput();

  /* USER CODE END 2 */

  /* Infinite loop */
  /* USER CODE BEGIN WHILE */
	while (1)
	{

	//voltage = voltageraw;
		k_erpm = ((100000000 / (commutation_interval * 208 * 6)) * 6)/10 ;

		count++;
		if (count > 100000) {
			count = 0;
		}
		compit = 0;
		if (HAL_IWDG_Refresh(&hiwdg) != HAL_OK)              // watchdog refresh
				{
			/* Refresh Error */
			Error_Handler();
		}
		control_loop_count++;
		if (control_loop_count > 2) {

			control_loop_count = 0;

			//	  		1-5: beep (1= low freq. 5 = high freq.)
			//	  		6: ESC info request (FW Version and SN sent over the tlm wire)
			//	  		7: rotate in one direction
			//	  		8: rotate in the other direction
			//	  		9: 3d mode off
			//	  		10: 3d mode on
			//	  		11: ESC settings request (saved settings over the TLM wire) (planed but not there yet)
			//	  		12: save Settings

			if (dshotcommand > 0) {
				if (dshotcommand == 2) {
					playInputTune();
				}
				if (dshotcommand == 21) {
					forward = dir_reversed;

				}
				if (dshotcommand == 20) {     // forward = 1 if dir_reversed = 0
					forward = 1 - dir_reversed;
				}
				if (dshotcommand == 7) {
					dir_reversed = 0;

				}
				if (dshotcommand == 8) {
					dir_reversed = 1;

				}
				if (dshotcommand == 9) {
					bi_direction = 0;
					armed = 0;

				}
				if (dshotcommand == 10) {
					bi_direction = 1;
					armed = 0;
				}
				if (dshotcommand == 12) {
					storeEEpromConfig();
					while (1) {   // resets esc as iwdg times out

					}
				}
				dshotcommand = 0;
			}

			if (bi_direction == 1 && (proshot == 0 && dshot == 0)) {
				//char oldbrake = brake;

				if (newinput > 1100) {
					if (forward == dir_reversed) {
						adjusted_input = 0;
						prop_brake_active = 1;
						brushed_direction_set = 0;
						forward = 1 - dir_reversed;
						//	HAL_Delay(1);
					}

					if (prop_brake_active == 0) {

						adjusted_input = (newinput - 1050) * 3;
						//	tempbrake = 0;
						//	}
					}
				}
				if (newinput < 760) {
					if (forward == (1 - dir_reversed)) {
						prop_brake_active = 1;
						adjusted_input = 0;
						forward = dir_reversed;
						brushed_direction_set = 0;

					}
					if (prop_brake_active == 0) {
						adjusted_input = ((760 - newinput) * 3) + 100;

					}
					//	tempbrake = 0;
				}
			//	if (zctimeout >= zc_timeout_threshold) {
					//	adjusted_input = 0;
					if (vehicle_mode != 3) { // car mode requires throttle return to center before direction change
						prop_brake_active = 0;
			//		}

			//		startupcountdown = 0;
			//		bemf_counts = 0;
				}

				if (newinput >= 760 && newinput < 1100) {
					adjusted_input = 0;
					prop_brake_active = 0;
				}

			} else if ((proshot || dshot) && bi_direction) {
				if (newinput > 1097) {

					if (forward == dir_reversed) {
						forward = 1 - dir_reversed;
						bemf_counts = 0;
						brushed_direction_set = 0;
					}
					adjusted_input = (newinput - 1100) * 2 + 100;
				}
				if (newinput <= 1047 && newinput > 0) {
				//	startcount++;

					if (forward == (1 - dir_reversed)) {
						bemf_counts = 0;
						forward = dir_reversed;
						brushed_direction_set = 0;

					}
					adjusted_input = (newinput - 90) * 2;
				}
				if ((newinput > 1047 && newinput < 1098) || newinput <= 120) {
					adjusted_input = 0;
				}

			} else {
				adjusted_input = newinput;
			}

			//	if ((adjusted_input > 100)&&(startupcountdown>250)){
			if (adjusted_input > 2000) {
				adjusted_input = 2000;
			}

//			if ((adjusted_input - input > 5 && bemf_counts < 50)) {
//				input = input + 1;
//			//	advance_multiplier = 12;
//			} else if ((input - adjusted_input > 5) && ( bemf_counts < 50)) {
//				input = input - 1;
//			} else {
				input = adjusted_input;
			//	advance_multiplier = map((commutation_interval), 150, 300, 8, 8);
	//		}

		}

//		if ( commutation_interval < 120 ){        // desync
//		input = 0;
//		}
if(brushed_mode){
dither_count++;
if(dither_count > 2){
	dither_count = 0;
}
if(input > 1990){               // keep slightly below 100 percent duty cycle for some drivers
	input = 1990;
}
bemf_counts = 200;

if(!brushed_direction_set && !prop_brake_active){

if (!bi_polar){
	if(forward){
		comStep(6);
	}else{
		comStep(3);
	}
	brushed_direction_set = 1;
}else{      // bipolar pwm  caution!!
	phaseAPWM();
	phaseCPWM();
		brushed_direction_set = 1;
}
}
}
//		if (bemf_counts > 100){                      // NEVER TURN THIS ON!!! for musement only
//bemf_counts = 0;
//		input=0;
//		forward = 1-forward;
//			dir_reversed = 1-dir_reversed;
//
//		}

//		if (duty_cycle < 500 && commutation_interval < 200){         // stuck commutation at pwm speed
//			zctimeout = zc_timeout_threshold;
//		}

		advance_multiplier = map((commutation_interval), 150, 3000, 16, 8);
		if (inputSet == 0) {
			HAL_Delay(10);
			detectInput();

		}
		if (!armed) {
				if ((inputSet == 1) && (input == 0)) {
					armedcount++;
					HAL_Delay(1);
					if (armedcount > 2000) {
						armed = 1;
						playInputTune();
					}
				}
				if (input > 0) {
					armedcount = 0;
				}
			}

		if ((input > 47) && (armed == 1)) {
			prop_brake_active = 0;
			started = 1;
			start_power = map((input), 47, 1998, 150, 600);

			if((input - 60) > duty_cycle){
				duty_cycle +=2;
			}
			if((input - 60) < duty_cycle){
				duty_cycle -=2;
			}
		//	duty_cycle = input  - 20;

			if (bemf_counts < 20) {
//				if (duty_cycle < 150) {
//					duty_cycle = 150;
//				}
				if (duty_cycle > 500) {
					duty_cycle = 500;
				}
			}

			if (bemf_counts < 5 ){

					duty_cycle = start_power;

			}

			if (running) {
				if (duty_cycle > 1998) {                             // safety!!!
					duty_cycle = 1998;
				}
				if (duty_cycle < 90) {
					duty_cycle = 90;
				}

				if(bi_polar){
                 if (dither_count == 0){
				 if (forward){
					TIM1->CCR2 = (TIM1->ARR /2) + (input / 2);
					TIM1->CCR3 = (TIM1->ARR /2) - (input / 2);
				 }else{
					 TIM1->CCR2 = (TIM1->ARR /2) - (input / 2);
					 TIM1->CCR3 = (TIM1->ARR /2) + (input / 2);
				 }
                 }
                 if (dither_count == 1){
                 				 if (forward){
                 					TIM1->CCR2 = (TIM1->ARR /2) + (input / 2) + dither_amount;
                 					TIM1->CCR3 = (TIM1->ARR /2) - (input / 2) - dither_amount;
                 				 }else{
                 					 TIM1->CCR2 = (TIM1->ARR /2) - (input / 2)- dither_amount;
                 					 TIM1->CCR3 = (TIM1->ARR /2) + (input / 2) + dither_amount;
                 				 }
                                  }
                 if (dither_count == 2){
                 				 if (forward){
                 					TIM1->CCR2 = (TIM1->ARR /2) + (input / 2)- dither_amount;
                 					TIM1->CCR3 = (TIM1->ARR /2) - (input / 2) + dither_amount;
                 				 }else{
                 					 TIM1->CCR2 = (TIM1->ARR /2) - (input / 2) + dither_amount;
                 					 TIM1->CCR3 = (TIM1->ARR /2) + (input / 2) - dither_amount;
                 				 }
                                  }
				}else{
				TIM1->CCR1 = duty_cycle;
				TIM1->CCR2 = duty_cycle;
				TIM1->CCR3 = duty_cycle;
				//	TIM1->CCR4 = duty_cycle;
				}
			}

		}
		//

		signaltimeout++;
		if (signaltimeout > signal_timeout_threshold) {
			input = 0;
			armed = 0;
			armedcount = 0;
			error = 1;
			inputSet = 0;
			TIM15->PSC=0;
			TIM16->PSC=0;
			dshot = 0;
			proshot = 0;
			servoPwm = 0;
			HAL_TIM_Base_Start_IT(&htim16);
			IC_buffer_size = 64;
			for (int i=0; i < 64; i++){
				dma_buffer[i] = 0;
			}
			HAL_TIM_IC_Start_DMA(&htim15, TIM_CHANNEL_1, dma_buffer , 64);
			//	  duty_cycle = 0;          //mid point
		}

		if (input <= 47) {
	        if((brushed_mode) && (brushed_direction_set)){

	        	brushed_direction_set = 0;
	        }
			if (brake == 1){
			EXTI->IMR &= ~(1 << 21);
			}
			//	sensorless = 0;
			forcedcomcount = 0;
			started = 0;
			//running = 0;
			if (!brake && !prop_brake_active) {
				allOff();
			}
			duty_cycle = 0;
			if ((brake || tempbrake)&& (!bi_polar)) {
				fullBrake();
				duty_cycle = 0;
				bemf_counts = 0;
				//	HAL_COMP_Stop_IT(&hcomp1);
			}

			if (prop_brake && prop_brake_active) {
				//	prop_brake_active = 1;
				duty_cycle = prop_brake_strength;
				proBrake();
			}

			if(bi_polar){
				TIM1->CCR2 = (TIM1->ARR) / 2;
				TIM1->CCR3 = (TIM1->ARR) / 2;
			}else{
			TIM1->CCR1 = duty_cycle;// set duty cycle to 50 out of 768 to start.
			TIM1->CCR2 = duty_cycle;
			TIM1->CCR3 = duty_cycle;
			}
//					if (commutation_interval > 60000){
//						HAL_COMP_Stop_IT(&hcomp1);
//					//	prop_brake_active = 0;
//					}

		}
//		if (bemf_counts < 100) {

		if (vehicle_mode == 1){
		if (bemf_counts < 40 || commutation_interval > 2000 || duty_cycle < 200) {
			filter_delay = 15;
			filter_level = 10;
		} else {
			filter_level = 5;

			filter_delay = 0;
		}
		if (duty_cycle > 600 && bemf_counts > 75){
			filter_level = 2;
		//	filter_delay = 0;
		}

		if (commutation_interval < 200 && bemf_counts > 100){
			filter_level = 2;
		}

		}

		if (vehicle_mode == 2|| vehicle_mode == 3 ) {    // crawler much fewer poles, much more filtering time needed
			if (bemf_counts < 25 || commutation_interval > 8000 || duty_cycle < 200) {
				filter_delay = 15;
				filter_level = 15;
			} else {
				filter_level = 8;

				filter_delay = 0;
			}
		}
		if (vehicle_mode == 5 ){

		if(bemf_counts < 15 || commutation_interval > 25000){
			filter_level = 10;
		}else{
			filter_level = 2;
		}
		}

		if (started == 1) {
			if (running == 0) {
				if(brushed_mode){
					running = 1;
				}else{

				zctimeout = 0;
				startMotor(); // safety on for input testing   ************************************************
				}
			}
		}

		if (polling_mode && running == 1){
			checkForZeroCross();

//			if ((TIM2->CNT > (commutation_interval + commutation_interval / 2)) && commutation_interval > 10000 ){
//				if(!forced_com_done){
//					commutate();
//					TIM2->CNT = 0;
//					forced_com_done = 1;
//				}
//			}
		}

if(!brushed_mode){
//		if (duty_cycle < 300 && bemf_counts > 10) {
//			zc_timeout_threshold = 800;
//		} else {
//			zc_timeout_threshold = 700;
//		}
////		if (TIM3->CNT > 60000 && duty_cycle < 1000){
////			running = 0;
////			started = 0;
////			EXTI->IMR &= ~(1 << 21);
////			EXTI->PR &=~(1 << 21);
////			//input = 0;
////
////		}
	zctimeout++;
		if (zctimeout > zc_timeout_threshold) {
			bemf_counts = 0;
			//		prop_brake_active = 0;
			bad_commutation = 0;
			sensorless = 0;
			EXTI->IMR &= (0 << 21);
		//	HAL_COMP_Stop_IT(&hcomp1);
			count++;
			running = 0;
		//	duty_cycle = 0;
		}

}

//		if ((bemf_counts > 15
//				&& TIM3->CNT > commutation_interval + commutation_interval / 2)
//				&& duty_cycle < 300) {
//			if (forcedcount < 1) {
//				forcedcount++;
//				forcedCommutation();
//			}
//		//	bemf_counts = 0;
//		}

  /* USER CODE END WHILE */

  /* USER CODE BEGIN 3 */
////			}
////		}
	}
  /* USER CODE END 3 */

}

/** System Clock Configuration
*/
void SystemClock_Config(void)
{

  RCC_OscInitTypeDef RCC_OscInitStruct;
  RCC_ClkInitTypeDef RCC_ClkInitStruct;

    /**Initializes the CPU, AHB and APB busses clocks
    */
  RCC_OscInitStruct.OscillatorType = RCC_OSCILLATORTYPE_HSI|RCC_OSCILLATORTYPE_HSI14
                              |RCC_OSCILLATORTYPE_LSI;
  RCC_OscInitStruct.HSIState = RCC_HSI_ON;
  RCC_OscInitStruct.HSI14State = RCC_HSI14_ON;
  RCC_OscInitStruct.HSICalibrationValue = 16;
  RCC_OscInitStruct.HSI14CalibrationValue = 16;
  RCC_OscInitStruct.LSIState = RCC_LSI_ON;
  RCC_OscInitStruct.PLL.PLLState = RCC_PLL_ON;
  RCC_OscInitStruct.PLL.PLLSource = RCC_PLLSOURCE_HSI;
  RCC_OscInitStruct.PLL.PLLMUL = RCC_PLL_MUL12;
  RCC_OscInitStruct.PLL.PREDIV = RCC_PREDIV_DIV1;
  if (HAL_RCC_OscConfig(&RCC_OscInitStruct) != HAL_OK)
  {
    _Error_Handler(__FILE__, __LINE__);
  }

    /**Initializes the CPU, AHB and APB busses clocks
    */
  RCC_ClkInitStruct.ClockType = RCC_CLOCKTYPE_HCLK|RCC_CLOCKTYPE_SYSCLK
                              |RCC_CLOCKTYPE_PCLK1;
  RCC_ClkInitStruct.SYSCLKSource = RCC_SYSCLKSOURCE_PLLCLK;
  RCC_ClkInitStruct.AHBCLKDivider = RCC_SYSCLK_DIV1;
  RCC_ClkInitStruct.APB1CLKDivider = RCC_HCLK_DIV1;

  if (HAL_RCC_ClockConfig(&RCC_ClkInitStruct, FLASH_LATENCY_1) != HAL_OK)
  {
    _Error_Handler(__FILE__, __LINE__);
  }

    /**Configure the Systick interrupt time
    */
  HAL_SYSTICK_Config(HAL_RCC_GetHCLKFreq()/1000);

    /**Configure the Systick
    */
  HAL_SYSTICK_CLKSourceConfig(SYSTICK_CLKSOURCE_HCLK);

  /* SysTick_IRQn interrupt configuration */
  HAL_NVIC_SetPriority(SysTick_IRQn, 0, 0);
}

/* ADC init function */
static void MX_ADC_Init(void)
{

  ADC_ChannelConfTypeDef sConfig;

    /**Configure the global features of the ADC (Clock, Resolution, Data Alignment and number of conversion)
    */
  hadc.Instance = ADC1;
  hadc.Init.ClockPrescaler = ADC_CLOCK_ASYNC_DIV1;
  hadc.Init.Resolution = ADC_RESOLUTION_12B;
  hadc.Init.DataAlign = ADC_DATAALIGN_RIGHT;
  hadc.Init.ScanConvMode = ADC_SCAN_DIRECTION_FORWARD;
  hadc.Init.EOCSelection = ADC_EOC_SEQ_CONV;
  hadc.Init.LowPowerAutoWait = DISABLE;
  hadc.Init.LowPowerAutoPowerOff = DISABLE;
  hadc.Init.ContinuousConvMode = DISABLE;
  hadc.Init.DiscontinuousConvMode = ENABLE;
  hadc.Init.ExternalTrigConv = ADC_EXTERNALTRIGCONV_T1_CC4;
  hadc.Init.ExternalTrigConvEdge = ADC_EXTERNALTRIGCONVEDGE_RISING;
  hadc.Init.DMAContinuousRequests = ENABLE;
  hadc.Init.Overrun = ADC_OVR_DATA_PRESERVED;
  if (HAL_ADC_Init(&hadc) != HAL_OK)
  {
    _Error_Handler(__FILE__, __LINE__);
  }

    /**Configure for the selected ADC regular channel to be converted.
    */
  sConfig.Channel = ADC_CHANNEL_6;
  sConfig.Rank = ADC_RANK_CHANNEL_NUMBER;
  sConfig.SamplingTime = ADC_SAMPLETIME_28CYCLES_5;
  if (HAL_ADC_ConfigChannel(&hadc, &sConfig) != HAL_OK)
  {
    _Error_Handler(__FILE__, __LINE__);
  }

    /**Configure for the selected ADC regular channel to be converted.
    */
//  sConfig.Channel = ADC_CHANNEL_3;
//  if (HAL_ADC_ConfigChannel(&hadc, &sConfig) != HAL_OK)
//  {
//    _Error_Handler(__FILE__, __LINE__);
//  }

    /**Configure for the selected ADC regular channel to be converted.
    */
  sConfig.Channel = ADC_CHANNEL_TEMPSENSOR;
  if (HAL_ADC_ConfigChannel(&hadc, &sConfig) != HAL_OK)
  {
    _Error_Handler(__FILE__, __LINE__);
  }

}

/* COMP1 init function */
static void MX_COMP1_Init(void)
{

  hcomp1.Instance = COMP1;
  hcomp1.Init.InvertingInput = COMP_INVERTINGINPUT_DAC1;
  hcomp1.Init.NonInvertingInput = COMP_NONINVERTINGINPUT_IO1;
  hcomp1.Init.Output = COMP_OUTPUT_NONE;
  hcomp1.Init.OutputPol = COMP_OUTPUTPOL_NONINVERTED;
  hcomp1.Init.Hysteresis = COMP_HYSTERESIS_NONE;
  hcomp1.Init.Mode = COMP_MODE_HIGHSPEED;
  hcomp1.Init.WindowMode = COMP_WINDOWMODE_DISABLE;
  hcomp1.Init.TriggerMode = COMP_TRIGGERMODE_IT_RISING;
  if (HAL_COMP_Init(&hcomp1) != HAL_OK)
  {
    _Error_Handler(__FILE__, __LINE__);
  }

}

/* IWDG init function */
static void MX_IWDG_Init(void)
{

	hiwdg.Instance = IWDG;
	hiwdg.Init.Prescaler = IWDG_PRESCALER_16;
	hiwdg.Init.Window = IWDG_WINDOW_DISABLE;
	hiwdg.Init.Reload = 4000;
	if (HAL_IWDG_Init(&hiwdg) != HAL_OK)
	{
		_Error_Handler(__FILE__, __LINE__);
	}

}

/* TIM1 init function */
static void MX_TIM1_Init(void)
{

  TIM_ClockConfigTypeDef sClockSourceConfig;
  TIM_MasterConfigTypeDef sMasterConfig;
  TIM_OC_InitTypeDef sConfigOC;
  TIM_BreakDeadTimeConfigTypeDef sBreakDeadTimeConfig;

  htim1.Instance = TIM1;
  htim1.Init.Prescaler = 0;
  htim1.Init.CounterMode = TIM_COUNTERMODE_UP;
  htim1.Init.Period = 1999;
  htim1.Init.ClockDivision = TIM_CLOCKDIVISION_DIV1;
  htim1.Init.RepetitionCounter = 0;
  htim1.Init.AutoReloadPreload = TIM_AUTORELOAD_PRELOAD_DISABLE;
  if (HAL_TIM_Base_Init(&htim1) != HAL_OK)
  {
    _Error_Handler(__FILE__, __LINE__);
  }

  sClockSourceConfig.ClockSource = TIM_CLOCKSOURCE_INTERNAL;
  if (HAL_TIM_ConfigClockSource(&htim1, &sClockSourceConfig) != HAL_OK)
  {
    _Error_Handler(__FILE__, __LINE__);
  }

  if (HAL_TIM_PWM_Init(&htim1) != HAL_OK)
  {
    _Error_Handler(__FILE__, __LINE__);
  }

  sMasterConfig.MasterOutputTrigger = TIM_TRGO_RESET;
  sMasterConfig.MasterSlaveMode = TIM_MASTERSLAVEMODE_DISABLE;
  if (HAL_TIMEx_MasterConfigSynchronization(&htim1, &sMasterConfig) != HAL_OK)
  {
    _Error_Handler(__FILE__, __LINE__);
  }

  sConfigOC.OCMode = TIM_OCMODE_PWM1;
  sConfigOC.Pulse = 0;
  sConfigOC.OCPolarity = TIM_OCPOLARITY_HIGH;
  sConfigOC.OCNPolarity = TIM_OCNPOLARITY_HIGH;
  sConfigOC.OCFastMode = TIM_OCFAST_DISABLE;
  sConfigOC.OCIdleState = TIM_OCIDLESTATE_RESET;
  sConfigOC.OCNIdleState = TIM_OCNIDLESTATE_RESET;
  if (HAL_TIM_PWM_ConfigChannel(&htim1, &sConfigOC, TIM_CHANNEL_1) != HAL_OK)
  {
    _Error_Handler(__FILE__, __LINE__);
  }

  if (HAL_TIM_PWM_ConfigChannel(&htim1, &sConfigOC, TIM_CHANNEL_2) != HAL_OK)
  {
    _Error_Handler(__FILE__, __LINE__);
  }

  if (HAL_TIM_PWM_ConfigChannel(&htim1, &sConfigOC, TIM_CHANNEL_3) != HAL_OK)
  {
    _Error_Handler(__FILE__, __LINE__);
  }

  if (HAL_TIM_PWM_ConfigChannel(&htim1, &sConfigOC, TIM_CHANNEL_4) != HAL_OK)
  {
    _Error_Handler(__FILE__, __LINE__);
  }

  sBreakDeadTimeConfig.OffStateRunMode = TIM_OSSR_DISABLE;
  sBreakDeadTimeConfig.OffStateIDLEMode = TIM_OSSI_DISABLE;
  sBreakDeadTimeConfig.LockLevel = TIM_LOCKLEVEL_OFF;
  sBreakDeadTimeConfig.DeadTime = 80;
  sBreakDeadTimeConfig.BreakState = TIM_BREAK_DISABLE;
  sBreakDeadTimeConfig.BreakPolarity = TIM_BREAKPOLARITY_HIGH;
  sBreakDeadTimeConfig.AutomaticOutput = TIM_AUTOMATICOUTPUT_DISABLE;
  if (HAL_TIMEx_ConfigBreakDeadTime(&htim1, &sBreakDeadTimeConfig) != HAL_OK)
  {
    _Error_Handler(__FILE__, __LINE__);
  }

  HAL_TIM_MspPostInit(&htim1);

}

/* TIM2 init function */
static void MX_TIM2_Init(void)
{

  TIM_ClockConfigTypeDef sClockSourceConfig;
  TIM_MasterConfigTypeDef sMasterConfig;

  htim2.Instance = TIM2;
  htim2.Init.Prescaler = 10;
  htim2.Init.CounterMode = TIM_COUNTERMODE_UP;
  htim2.Init.Period = 126000;
  htim2.Init.ClockDivision = TIM_CLOCKDIVISION_DIV1;
  htim2.Init.AutoReloadPreload = TIM_AUTORELOAD_PRELOAD_DISABLE;
  if (HAL_TIM_Base_Init(&htim2) != HAL_OK)
  {
    _Error_Handler(__FILE__, __LINE__);
  }

  sClockSourceConfig.ClockSource = TIM_CLOCKSOURCE_INTERNAL;
  if (HAL_TIM_ConfigClockSource(&htim2, &sClockSourceConfig) != HAL_OK)
  {
    _Error_Handler(__FILE__, __LINE__);
  }

  sMasterConfig.MasterOutputTrigger = TIM_TRGO_RESET;
  sMasterConfig.MasterSlaveMode = TIM_MASTERSLAVEMODE_DISABLE;
  if (HAL_TIMEx_MasterConfigSynchronization(&htim2, &sMasterConfig) != HAL_OK)
  {
    _Error_Handler(__FILE__, __LINE__);
  }

}

/* TIM3 init function */
static void MX_TIM3_Init(void)
{

  TIM_ClockConfigTypeDef sClockSourceConfig;
  TIM_MasterConfigTypeDef sMasterConfig;

  htim3.Instance = TIM3;
  htim3.Init.Prescaler = 10;
  htim3.Init.CounterMode = TIM_COUNTERMODE_UP;
  htim3.Init.Period = 65535;
  htim3.Init.ClockDivision = TIM_CLOCKDIVISION_DIV1;
  htim3.Init.AutoReloadPreload = TIM_AUTORELOAD_PRELOAD_DISABLE;
  if (HAL_TIM_Base_Init(&htim3) != HAL_OK)
  {
    _Error_Handler(__FILE__, __LINE__);
  }

  sClockSourceConfig.ClockSource = TIM_CLOCKSOURCE_INTERNAL;
  if (HAL_TIM_ConfigClockSource(&htim3, &sClockSourceConfig) != HAL_OK)
  {
    _Error_Handler(__FILE__, __LINE__);
  }

  sMasterConfig.MasterOutputTrigger = TIM_TRGO_RESET;
  sMasterConfig.MasterSlaveMode = TIM_MASTERSLAVEMODE_DISABLE;
  if (HAL_TIMEx_MasterConfigSynchronization(&htim3, &sMasterConfig) != HAL_OK)
  {
    _Error_Handler(__FILE__, __LINE__);
  }

}

/* TIM15 init function */
static void MX_TIM15_Init(void)
{

  TIM_SlaveConfigTypeDef sSlaveConfig;
  TIM_MasterConfigTypeDef sMasterConfig;
  TIM_IC_InitTypeDef sConfigIC;

  htim15.Instance = TIM15;
  htim15.Init.Prescaler = 0;
  htim15.Init.CounterMode = TIM_COUNTERMODE_UP;
  htim15.Init.Period = 0xffff;
  htim15.Init.ClockDivision = TIM_CLOCKDIVISION_DIV1;
  htim15.Init.RepetitionCounter = 0;
  htim15.Init.AutoReloadPreload = TIM_AUTORELOAD_PRELOAD_DISABLE;
  if (HAL_TIM_Base_Init(&htim15) != HAL_OK)
  {
    _Error_Handler(__FILE__, __LINE__);
  }

  if (HAL_TIM_IC_Init(&htim15) != HAL_OK)
  {
    _Error_Handler(__FILE__, __LINE__);
  }

  sSlaveConfig.SlaveMode = TIM_SLAVEMODE_RESET;
  sSlaveConfig.InputTrigger = TIM_TS_TI1FP1;
  sSlaveConfig.TriggerPolarity = TIM_INPUTCHANNELPOLARITY_BOTHEDGE;
  sSlaveConfig.TriggerFilter = 0;
  if (HAL_TIM_SlaveConfigSynchronization(&htim15, &sSlaveConfig) != HAL_OK)
  {
    _Error_Handler(__FILE__, __LINE__);
  }

  sMasterConfig.MasterOutputTrigger = TIM_TRGO_RESET;
  sMasterConfig.MasterSlaveMode = TIM_MASTERSLAVEMODE_DISABLE;
  if (HAL_TIMEx_MasterConfigSynchronization(&htim15, &sMasterConfig) != HAL_OK)
  {
    _Error_Handler(__FILE__, __LINE__);
  }

  sConfigIC.ICPolarity = TIM_INPUTCHANNELPOLARITY_BOTHEDGE;
  sConfigIC.ICSelection = TIM_ICSELECTION_DIRECTTI;
  sConfigIC.ICPrescaler = TIM_ICPSC_DIV1;
  sConfigIC.ICFilter = 0;
  if (HAL_TIM_IC_ConfigChannel(&htim15, &sConfigIC, TIM_CHANNEL_1) != HAL_OK)
  {
    _Error_Handler(__FILE__, __LINE__);
  }

}

/* TIM16 init function */
static void MX_TIM16_Init(void)
{

  htim16.Instance = TIM16;
  htim16.Init.Prescaler = 0;
  htim16.Init.CounterMode = TIM_COUNTERMODE_UP;
  htim16.Init.Period = 9000;
  htim16.Init.ClockDivision = TIM_CLOCKDIVISION_DIV1;
  htim16.Init.RepetitionCounter = 0;
  htim16.Init.AutoReloadPreload = TIM_AUTORELOAD_PRELOAD_DISABLE;
  if (HAL_TIM_Base_Init(&htim16) != HAL_OK)
  {
    _Error_Handler(__FILE__, __LINE__);
  }

}

static void MX_DMA_Init(void)
{
  /* DMA controller clock enable */
  __HAL_RCC_DMA1_CLK_ENABLE();

  /* DMA interrupt init */
  /* DMA1_Channel1_IRQn interrupt configuration */
  HAL_NVIC_SetPriority(DMA1_Channel1_IRQn, 2, 0);
  HAL_NVIC_EnableIRQ(DMA1_Channel1_IRQn);
  /* DMA1_Channel4_5_IRQn interrupt configuration */
  HAL_NVIC_SetPriority(DMA1_Channel4_5_IRQn, 2, 0);
  HAL_NVIC_EnableIRQ(DMA1_Channel4_5_IRQn);

}

/** Configure pins as
        * Analog
        * Input
        * Output
        * EVENT_OUT
        * EXTI
*/
static void MX_GPIO_Init(void)
{

  LL_GPIO_InitTypeDef GPIO_InitStruct;

  /* GPIO Ports Clock Enable */
  LL_AHB1_GRP1_EnableClock(LL_AHB1_GRP1_PERIPH_GPIOA);
  LL_AHB1_GRP1_EnableClock(LL_AHB1_GRP1_PERIPH_GPIOB);

  /**/
  LL_GPIO_ResetOutputPin(GPIOA, LL_GPIO_PIN_15);

  /**/
  GPIO_InitStruct.Pin = LL_GPIO_PIN_15;
  GPIO_InitStruct.Mode = LL_GPIO_MODE_OUTPUT;
  GPIO_InitStruct.Speed = LL_GPIO_SPEED_FREQ_LOW;
  GPIO_InitStruct.OutputType = LL_GPIO_OUTPUT_PUSHPULL;
  GPIO_InitStruct.Pull = LL_GPIO_PULL_NO;
  LL_GPIO_Init(GPIOA, &GPIO_InitStruct);

}

void _Error_Handler(char * file, int line)
{
	while(1)
	{
	}
}

/************************ (C) COPYRIGHT STMicroelectronics *****END OF FILE****/
